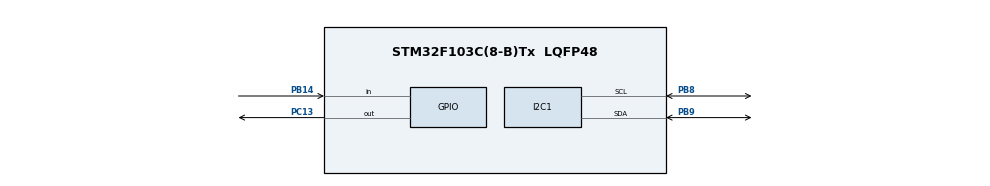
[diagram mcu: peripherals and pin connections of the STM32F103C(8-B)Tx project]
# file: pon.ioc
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FREERTOS.Tasks01=defaultTask,24,128,StartDefaultTask,Default,NULL,Dynamic,NULL,NULL;BTNTask,40,128,buttonTask,Default,NULL,Dynamic,NULL,NULL;LCDTask,24,128,ledTask,Default,NULL,Dynamic,NULL,NULL;holdLED,16,128,lcdTask,Default,NULL,Dynamic,NULL,NULL
Mcu.Family=STM32F1
Mcu.Name=STM32F103C(8-B)Tx
Mcu.Package=LQFP48
NVIC.PriorityGroup=NVIC_PRIORITYGROUP_4
PB14.GPIO_PuPd=GPIO_PULLUP
PB14.Signal=GPIO_Input
PB8.Mode=I2C
PB8.Signal=I2C1_SCL
PB9.Mode=I2C
PB9.Signal=I2C1_SDA
PC13-TAMPER-RTC.PinState=GPIO_PIN_SET
PC13-TAMPER-RTC.Signal=GPIO_Output
ProjectManager.HeapSize=0x200
ProjectManager.StackSize=0x400
ProjectManager.TargetToolchain=STM32CubeIDE
RCC.APB1Freq_Value=8000000
RCC.APB2Freq_Value=8000000
VP_FREERTOS_VS_CMSIS_V2.Mode=CMSIS_V2
board=custom

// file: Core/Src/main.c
/* USER CODE BEGIN Header */
/**
  ******************************************************************************
  * @file           : main.c
  * @brief          : Main program body
  ******************************************************************************
  * @attention
  *
  * Copyright (c) 2025 STMicroelectronics.
  * All rights reserved.
  *
  * This software is licensed under terms that can be found in the LICENSE file
  * in the root directory of this software component.
  * If no LICENSE file comes with this software, it is provided AS-IS.
  *
  ******************************************************************************
  */
/* USER CODE END Header */
#include "main.h"
#include "cmsis_os.h"

/* USER CODE BEGIN Includes */
#include <stdio.h>
#include <string.h>
#include "liquidcrystal_i2c.h"

/* USER CODE END Includes */

I2C_HandleTypeDef hi2c1;

/* Definitions for defaultTask */
osThreadId_t defaultTaskHandle;

osSemaphoreId_t buttonSemaphoreHandle;

const osThreadAttr_t defaultTask_attributes = {
  .name = "defaultTask",
  .stack_size = 128 * 4,
  .priority = (osPriority_t) osPriorityNormal,
};
/* Definitions for BTNTask */
osThreadId_t BTNTaskHandle;
const osThreadAttr_t BTNTask_attributes = {
  .name = "BTNTask",
  .stack_size = 128 * 4,
  .priority = (osPriority_t) osPriorityHigh,
};
/* Definitions for LCDTask */
osThreadId_t LCDTaskHandle;
const osThreadAttr_t LCDTask_attributes = {
  .name = "LCDTask",
  .stack_size = 128 * 4,
  .priority = (osPriority_t) osPriorityNormal,
};
/* Definitions for holdLED */
osThreadId_t holdLEDHandle;
const osThreadAttr_t holdLED_attributes = {
  .name = "holdLED",
  .stack_size = 128 * 4,
  .priority = (osPriority_t) osPriorityBelowNormal,
};

void SystemClock_Config(void);
static void MX_GPIO_Init(void);
static void MX_I2C1_Init(void);
void StartDefaultTask(void *argument);
void buttonTask(void *argument);
void ledTask(void *argument);
void lcdTask(void *argument);

/* USER CODE BEGIN 0 */

/*const osMessageQueueAttr_t buttonQueue_attributes = {
  .name = "buttonQueue"
}; */

const osSemaphoreAttr_t buttonSemaphore_attributes = {
  .name = "buttonSemaphore"
};

//volatile uint8_t button_pressed = 0;
/* USER CODE END 0 */

int main(void)
{

  /* MCU Configuration--------------------------------------------------------*/

  /* Reset of all peripherals, Initializes the Flash interface and the Systick. */
  HAL_Init();

  /* Configure the system clock */
  SystemClock_Config();

  /* Initialize all configured peripherals */
  MX_GPIO_Init();
  MX_I2C1_Init();
  /* USER CODE BEGIN 2 */
    HD44780_Init(2);
    HD44780_Clear();
    HD44780_SetCursor(0,0);
    HD44780_PrintStr("BTN don't push");
   /* buttonQueueHandle = osMessageQueueNew(1, sizeof(uint8_t), &buttonQueue_attributes); */
  /* USER CODE END 2 */

  /* Init scheduler */
  osKernelInitialize();

  /* USER CODE BEGIN RTOS_SEMAPHORES */
  /* add semaphores, ... */
  buttonSemaphoreHandle = osSemaphoreNew(1, 0, &buttonSemaphore_attributes);
  /* USER CODE END RTOS_SEMAPHORES */

  /* Create the thread(s) */
  /* creation of defaultTask */
  defaultTaskHandle = osThreadNew(StartDefaultTask, NULL, &defaultTask_attributes);

  /* creation of BTNTask */
  BTNTaskHandle = osThreadNew(buttonTask, NULL, &BTNTask_attributes);

  /* creation of LCDTask */
  LCDTaskHandle = osThreadNew(ledTask, NULL, &LCDTask_attributes);

  /* creation of holdLED */
  holdLEDHandle = osThreadNew(lcdTask, NULL, &holdLED_attributes);

  /* Start scheduler */
  osKernelStart();
  /* We should never get here as control is now taken by the scheduler */
  /* Infinite loop */
  while (1)
  {

  }
}

void SystemClock_Config(void)
{
  RCC_OscInitTypeDef RCC_OscInitStruct = {0};
  RCC_ClkInitTypeDef RCC_ClkInitStruct = {0};

  /** Initializes the RCC Oscillators according to the specified parameters
  * in the RCC_OscInitTypeDef structure.
  */
  RCC_OscInitStruct.OscillatorType = RCC_OSCILLATORTYPE_HSI;
  RCC_OscInitStruct.HSIState = RCC_HSI_ON;
  RCC_OscInitStruct.HSICalibrationValue = RCC_HSICALIBRATION_DEFAULT;
  RCC_OscInitStruct.PLL.PLLState = RCC_PLL_NONE;
  if (HAL_RCC_OscConfig(&RCC_OscInitStruct) != HAL_OK)
  {
    Error_Handler();
  }

  /** Initializes the CPU, AHB and APB buses clocks
  */
  RCC_ClkInitStruct.ClockType = RCC_CLOCKTYPE_HCLK|RCC_CLOCKTYPE_SYSCLK
                              |RCC_CLOCKTYPE_PCLK1|RCC_CLOCKTYPE_PCLK2;
  RCC_ClkInitStruct.SYSCLKSource = RCC_SYSCLKSOURCE_HSI;
  RCC_ClkInitStruct.AHBCLKDivider = RCC_SYSCLK_DIV1;
  RCC_ClkInitStruct.APB1CLKDivider = RCC_HCLK_DIV1;
  RCC_ClkInitStruct.APB2CLKDivider = RCC_HCLK_DIV1;

  if (HAL_RCC_ClockConfig(&RCC_ClkInitStruct, FLASH_LATENCY_0) != HAL_OK)
  {
    Error_Handler();
  }
}

static void MX_I2C1_Init(void)
{

  hi2c1.Instance = I2C1;
  hi2c1.Init.ClockSpeed = 100000;
  hi2c1.Init.DutyCycle = I2C_DUTYCYCLE_2;
  hi2c1.Init.OwnAddress1 = 0;
  hi2c1.Init.AddressingMode = I2C_ADDRESSINGMODE_7BIT;
  hi2c1.Init.DualAddressMode = I2C_DUALADDRESS_DISABLE;
  hi2c1.Init.OwnAddress2 = 0;
  hi2c1.Init.GeneralCallMode = I2C_GENERALCALL_DISABLE;
  hi2c1.Init.NoStretchMode = I2C_NOSTRETCH_DISABLE;
  if (HAL_I2C_Init(&hi2c1) != HAL_OK)
  {
    Error_Handler();
  }

}

static void MX_GPIO_Init(void)
{
  GPIO_InitTypeDef GPIO_InitStruct = {0};

  /* GPIO Ports Clock Enable */
  __HAL_RCC_GPIOC_CLK_ENABLE();
  __HAL_RCC_GPIOB_CLK_ENABLE();

  /*Configure GPIO pin Output Level */
  HAL_GPIO_WritePin(GPIOC, GPIO_PIN_13, GPIO_PIN_SET);

  /*Configure GPIO pin : PC13 */
  GPIO_InitStruct.Pin = GPIO_PIN_13;
  GPIO_InitStruct.Mode = GPIO_MODE_OUTPUT_PP;
  GPIO_InitStruct.Pull = GPIO_NOPULL;
  GPIO_InitStruct.Speed = GPIO_SPEED_FREQ_LOW;
  HAL_GPIO_Init(GPIOC, &GPIO_InitStruct);

  /*Configure GPIO pin : PB14 */
  GPIO_InitStruct.Pin = GPIO_PIN_14;
  GPIO_InitStruct.Mode = GPIO_MODE_INPUT;
  GPIO_InitStruct.Pull = GPIO_PULLUP;
  HAL_GPIO_Init(GPIOB, &GPIO_InitStruct);

}

void StartDefaultTask(void *argument)
{
  for(;;)
  {
    osDelay(1);
  }
}

void buttonTask(void *argument)
{
    uint8_t last_state = GPIO_PIN_SET; // предполагаем, что кнопка не нажата
    for(;;)
    {
        uint8_t current_state = HAL_GPIO_ReadPin(GPIOB, GPIO_PIN_14);
        if(current_state != last_state)
        {
            last_state = current_state;
            osSemaphoreRelease(buttonSemaphoreHandle); // сигнал об изменении состояния
        }
        osDelay(10);
    }
}

void ledTask(void *argument)
{
    uint8_t led_on = 0;
    for(;;)
    {
        // Ждем семафор с таймаутом 100 мс
        if(osSemaphoreAcquire(buttonSemaphoreHandle, 100) == osOK)
        {
            // получили сигнал об изменении, читаем актуальное состояние кнопки
        }
        uint8_t button_state = HAL_GPIO_ReadPin(GPIOB, GPIO_PIN_14);

        if(button_state == GPIO_PIN_RESET)
        {
            // Кнопка нажата — светодиод горит постоянно
            HAL_GPIO_WritePin(GPIOC, GPIO_PIN_13, GPIO_PIN_RESET);
            led_on = 1;

            osDelay(3000);
        }
        else
        {
            led_on = !led_on;
            HAL_GPIO_WritePin(GPIOC, GPIO_PIN_13, (led_on) ? GPIO_PIN_RESET : GPIO_PIN_SET);
        }
    }
}

void lcdTask(void *argument)
{
    uint8_t prev_state = 0xFF;
    for(;;)
    {
        // Ждем семафор с таймаутом 100 мс
        if(osSemaphoreAcquire(buttonSemaphoreHandle, 100) == osOK)
        {
            // получили сигнал об изменении, читаем актуальное состояние кнопки
        }
        uint8_t button_state = HAL_GPIO_ReadPin(GPIOB, GPIO_PIN_14);

        if(button_state != prev_state)
        {
            HD44780_Clear();
            HD44780_SetCursor(0,0);
            if(button_state == GPIO_PIN_RESET) {
                HD44780_PrintStr("door is open");

        }else {
        	int time = 3;
        	char buffer[20];

        	HD44780_Clear();
        	HD44780_PrintStr("door will be");
        	HD44780_SetCursor(0,1);

        	for (; time > 0; time--) {
            	HD44780_Clear();
                HD44780_SetCursor(0,0);
            	HD44780_PrintStr("door will be");
            	HD44780_SetCursor(0,1);
                sprintf(buffer, "close in: %d", time);
                HD44780_PrintStr(buffer);
                osDelay(900);
        	}
           	HD44780_Clear();
        	HD44780_SetCursor(0,0);
        	HD44780_PrintStr("door is close");

        }

            prev_state = button_state;

        }
        osDelay(50);
    }
}

void Error_Handler(void)
{
  __disable_irq();
  while (1)
  {
  }
}
